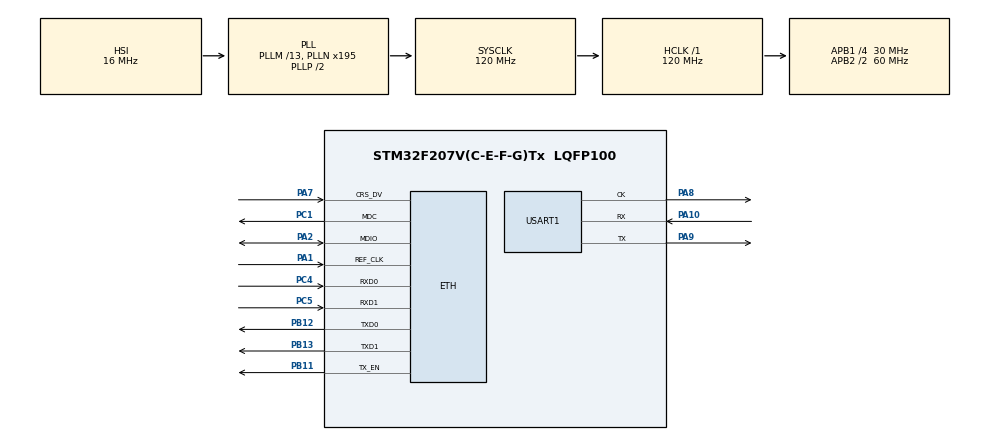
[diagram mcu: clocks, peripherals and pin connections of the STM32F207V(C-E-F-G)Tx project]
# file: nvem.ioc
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ETH.MediaInterface=ETH_MEDIA_INTERFACE_RMII
ETH.PhyAddress=1
FREERTOS.Tasks01=defaultTask,0,128,StartDefaultTask,Default,NULL,Dynamic,NULL,NULL
LWIP.GATEWAY_ADDRESS=192.168.000.001
LWIP.IP_ADDRESS=192.168.000.100
LWIP.LWIP_DHCP=0
LWIP.LWIP_LOOPBACK_MAX_PBUFS=16
LWIP.LWIP_NETIF_STATUS_CALLBACK=1
LWIP.NETMASK_ADDRESS=255.255.255.000
LWIP.Version=v2.0.3_Cube
Mcu.Family=STM32F2
Mcu.Name=STM32F207V(C-E-F-G)Tx
Mcu.Package=LQFP100
NVIC.ETH_IRQn=true\:5\:0\:true\:false\:true\:false\:false\:true
NVIC.PriorityGroup=NVIC_PRIORITYGROUP_4
NVIC.TIM1_UP_TIM10_IRQn=true\:0\:0\:false\:false\:true\:false\:false\:true
NVIC.TimeBase=TIM1_UP_TIM10_IRQn
NVIC.TimeBaseIP=TIM1
PA1.Mode=RMII
PA1.Signal=ETH_REF_CLK
PA10.Mode=Synchronous
PA10.Signal=USART1_RX
PA2.Mode=RMII
PA2.Signal=ETH_MDIO
PA7.Mode=RMII
PA7.Signal=ETH_CRS_DV
PA8.Mode=Synchronous
PA8.Signal=USART1_CK
PA9.Mode=Synchronous
PA9.Signal=USART1_TX
PB11.Mode=RMII
PB11.Signal=ETH_TX_EN
PB12.Mode=RMII
PB12.Signal=ETH_TXD0
PB13.Mode=RMII
PB13.Signal=ETH_TXD1
PC1.Mode=RMII
PC1.Signal=ETH_MDC
PC4.Mode=RMII
PC4.Signal=ETH_RXD0
PC5.Mode=RMII
PC5.Signal=ETH_RXD1
PH0-OSC_IN.Mode=HSE-External-Oscillator
PH0-OSC_IN.Signal=RCC_OSC_IN
PH1-OSC_OUT.Mode=HSE-External-Oscillator
PH1-OSC_OUT.Signal=RCC_OSC_OUT
ProjectManager.HeapSize=0x200
ProjectManager.StackSize=0x400
ProjectManager.TargetToolchain=TrueSTUDIO
RCC.48MHZClocksFreq_Value=60000000
RCC.AHBFreq_Value=120000000
RCC.APB1CLKDivider=RCC_HCLK_DIV4
RCC.APB1Freq_Value=30000000
RCC.APB1TimFreq_Value=60000000
RCC.APB2CLKDivider=RCC_HCLK_DIV2
RCC.APB2Freq_Value=60000000
RCC.APB2TimFreq_Value=120000000
RCC.CortexFreq_Value=120000000
RCC.HCLKFreq_Value=120000000
RCC.HSE_VALUE=25000000
RCC.HSI_VALUE=16000000
RCC.LSE_VALUE=32768
RCC.PLLM=13
RCC.PLLN=195
RCC.SYSCLKFreq_VALUE=120000000
RCC.SYSCLKSource=RCC_SYSCLKSOURCE_PLLCLK
RCC.VCOOutputFreq_Value=240000000
USART1.VirtualMode=VM_SYNC
VP_FREERTOS_VS_CMSIS_V1.Mode=CMSIS_V1
VP_LWIP_VS_Enabled.Mode=Enabled
VP_SYS_VS_tim1.Mode=TIM1
board=custom

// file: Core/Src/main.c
/* USER CODE END Header */
#include "main.h"
#include "cmsis_os.h"
#include "lwip.h"
#include "string.h"
#include "tcp.h"
#include "tinyg.h"					// #1 There are some dependencies
#include "config.h"					// #2
#include "hardware.h"
#include "persistence.h"
#include "controller.h"
#include "canonical_machine.h"
#include "report.h"
#include "planner.h"
#include "stepper.h"
#include "encoder.h"
#include "switch.h"
#include "test.h"
#include "pwm.h"
#include "xio.h"
USART_HandleTypeDef husart1;
struct netif gnetif; /* network interface structure */
osThreadId mainTaskHandle ;
void SystemClock_Config(void);
static void MX_GPIO_Init(void);
static void MX_USART1_Init(void);
void StartDefaultTask(void const * argument);
void tinyG(void const * argument);

void uartStr(char* s){
	HAL_USART_Transmit(&husart1, (uint8_t*)s, strlen(s), 1);
}

int main(void){
  /* Reset of all peripherals, Initializes the Flash interface and the Systick. */
  HAL_Init();
  /* Configure the system clock */
  SystemClock_Config();
  /* Initialize all configured peripherals */
  MX_GPIO_Init();
  MX_USART1_Init();
  //-------------------------------------------------------------------
  // mainTaskHandle
  osThreadDef(mTask, tinyG, osPriorityNormal, 0, 1024);
  mainTaskHandle = osThreadCreate(osThread(mTask), NULL);
  //__enable_irq();
  MX_LWIP_Init();
  printf("Start " __DATE__ " " __TIME__ " \r\n");//,HAL_RCC_GetPCLK2Freq());
  printf("Core clock %d MHz\r\n",(uint16_t)(SystemCoreClock / 1000000));
  printf("ST clock %d MHz\r\n",(uint16_t)(TIM_CLOCK / 1000000));
  printf("f= %f \r\n", 123.456);
  InitializeTelnetServer() ;
  /* Start scheduler */
  osKernelStart();
  //------------------------------------------------------------------------------------------------------------------

  /* We should never get here as control is now taken by the scheduler */
  while (1){

  }
}

void tinyG(void const * argument){

	stepper_timers_init();
	// do these next
	stepper_init(); 					// stepper subsystem 				- must precede gpio_init()
	encoder_init();						// virtual encoders
//--	switch_init();					// switches
//	gpio_init();						// parallel IO
//--	pwm_init();						// pulse width modulation drivers	- must follow gpio_init()

	controller_init();// must be first app init; reqs xio_init()
	config_init();						// config records from eeprom 		- must be next app init
	planner_init();						// motion planning subsystem
	canonical_machine_init();			// canonical machine				-
	rpt_print_system_ready_message();	// (LAST) announce system is ready

	for (;;) {
		controller_run( );			// single pass through the controller
	}
}
//
void SystemClock_Config(void){
  RCC_OscInitTypeDef RCC_OscInitStruct = {0};
  RCC_ClkInitTypeDef RCC_ClkInitStruct = {0};

  /** Initializes the RCC Oscillators according to the specified parameters
  * in the RCC_OscInitTypeDef structure.
  */
  RCC_OscInitStruct.OscillatorType = RCC_OSCILLATORTYPE_HSI;
  RCC_OscInitStruct.HSIState = RCC_HSI_ON;
  RCC_OscInitStruct.HSICalibrationValue = RCC_HSICALIBRATION_DEFAULT;
  RCC_OscInitStruct.PLL.PLLState = RCC_PLL_ON;
  RCC_OscInitStruct.PLL.PLLSource = RCC_PLLSOURCE_HSI;
  RCC_OscInitStruct.PLL.PLLM = 13;
  RCC_OscInitStruct.PLL.PLLN = 195;
  RCC_OscInitStruct.PLL.PLLP = RCC_PLLP_DIV2;
  RCC_OscInitStruct.PLL.PLLQ = 4;
  if (HAL_RCC_OscConfig(&RCC_OscInitStruct) != HAL_OK){
    Error_Handler();
  }
  /** Initializes the CPU, AHB and APB buses clocks
  */
  RCC_ClkInitStruct.ClockType = RCC_CLOCKTYPE_HCLK|RCC_CLOCKTYPE_SYSCLK|RCC_CLOCKTYPE_PCLK1|RCC_CLOCKTYPE_PCLK2;
  RCC_ClkInitStruct.SYSCLKSource = RCC_SYSCLKSOURCE_PLLCLK;
  RCC_ClkInitStruct.AHBCLKDivider = RCC_SYSCLK_DIV1;
  RCC_ClkInitStruct.APB1CLKDivider = RCC_HCLK_DIV4;
  RCC_ClkInitStruct.APB2CLKDivider = RCC_HCLK_DIV2;

  if (HAL_RCC_ClockConfig(&RCC_ClkInitStruct, FLASH_LATENCY_3) != HAL_OK)
  {
    Error_Handler();
  }
}

static void MX_USART1_Init(void){

  husart1.Instance = USART1;
  husart1.Init.BaudRate 	= 2000000;
  husart1.Init.WordLength = USART_WORDLENGTH_8B;
  husart1.Init.StopBits = USART_STOPBITS_1;
  husart1.Init.Parity = USART_PARITY_NONE;
  husart1.Init.Mode = USART_MODE_TX_RX;
  husart1.Init.CLKPolarity = USART_POLARITY_LOW;
  husart1.Init.CLKPhase = USART_PHASE_1EDGE;
  husart1.Init.CLKLastBit = USART_LASTBIT_DISABLE;
  if (HAL_USART_Init(&husart1) != HAL_OK){
    Error_Handler();
  }
}

static void MX_GPIO_Init(void){

  /* GPIO Ports Clock Enable */
  __HAL_RCC_GPIOH_CLK_ENABLE();
  __HAL_RCC_GPIOC_CLK_ENABLE();
  __HAL_RCC_GPIOA_CLK_ENABLE();
  __HAL_RCC_GPIOB_CLK_ENABLE();

  __HAL_RCC_GPIOE_CLK_ENABLE();
  __HAL_RCC_GPIOD_CLK_ENABLE();

}

void HAL_TIM_PeriodElapsedCallback(TIM_HandleTypeDef *htim){
  /* USER CODE BEGIN Callback 0 */
	static uint16_t ms ;
	/* USER CODE END Callback 0 */
	if (htim->Instance == TIM1) {
		HAL_IncTick();
		ms++;
		//
		if(ms >= 1000){
			/* toggle PA0 */
			//GPIOA -> ODR ^= GPIO_PIN_0;
			//sys.uptime++;
			ms = 0 ;
		}
	}
	/* USER CODE BEGIN Callback 1 */
	if (htim->Instance == TIM2) {
		IRQ_TIMER_DDA();
	}
	if (htim->Instance == TIM3) {
		IRQ_TIMER_DWELL();
		//printf("TIMER_DWELL \r\n");
	}
	if (htim->Instance == TIM4) {
		//printf("TIMER_LOAD \r\n");
		IRQ_TIMER_LOAD();
	}
	if (htim->Instance == TIM5) {
		//printf("TIMER_EXEC \r\n");
		IRQ_TIMER_EXEC();
	}
	/* USER CODE END Callback 1 */
}

void Error_Handler(void){
}
